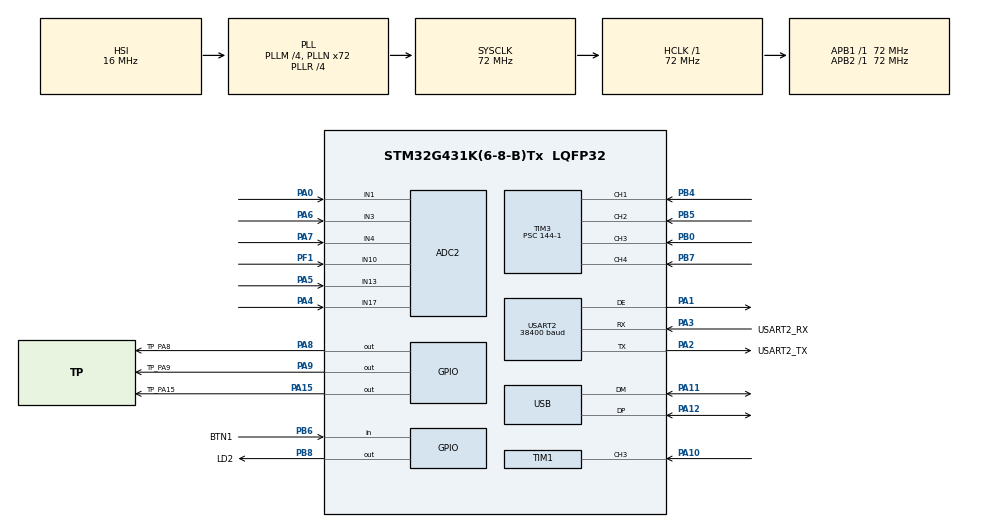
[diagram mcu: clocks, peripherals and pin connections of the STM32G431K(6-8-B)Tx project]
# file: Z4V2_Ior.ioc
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ADC1.Channel-0\#ChannelRegularConversion=ADC_CHANNEL_TEMPSENSOR_ADC1
ADC1.Channel-1\#ChannelRegularConversion=ADC_CHANNEL_VBAT
ADC1.Channel-2\#ChannelRegularConversion=ADC_CHANNEL_VREFINT
ADC1.DMAContinuousRequests=ENABLE
ADC1.ExternalTrigConv=ADC_EXTERNALTRIG_T7_TRGO
ADC1.NbrOfConversion=3
ADC1.NbrOfConversionFlag=1
ADC1.OffsetNumber-0\#ChannelRegularConversion=ADC_OFFSET_NONE
ADC1.OffsetNumber-1\#ChannelRegularConversion=ADC_OFFSET_NONE
ADC1.OffsetNumber-2\#ChannelRegularConversion=ADC_OFFSET_NONE
ADC1.Rank-0\#ChannelRegularConversion=1
ADC1.Rank-1\#ChannelRegularConversion=2
ADC1.Rank-2\#ChannelRegularConversion=3
ADC1.SamplingTime-0\#ChannelRegularConversion=ADC_SAMPLETIME_640CYCLES_5
ADC1.SamplingTime-1\#ChannelRegularConversion=ADC_SAMPLETIME_640CYCLES_5
ADC1.SamplingTime-2\#ChannelRegularConversion=ADC_SAMPLETIME_640CYCLES_5
ADC1.master=1
ADC2.Channel-0\#ChannelRegularConversion=ADC_CHANNEL_1
ADC2.Channel-1\#ChannelRegularConversion=ADC_CHANNEL_10
ADC2.Channel-2\#ChannelRegularConversion=ADC_CHANNEL_3
ADC2.Channel-3\#ChannelRegularConversion=ADC_CHANNEL_4
ADC2.Channel-4\#ChannelRegularConversion=ADC_CHANNEL_13
ADC2.Channel-5\#ChannelRegularConversion=ADC_CHANNEL_17
ADC2.DMAContinuousRequests=ENABLE
ADC2.ExternalTrigConv=ADC_EXTERNALTRIG_T8_TRGO
ADC2.NbrOfConversion=6
ADC2.NbrOfConversionFlag=1
ADC2.OffsetNumber-0\#ChannelRegularConversion=ADC_OFFSET_NONE
ADC2.OffsetNumber-1\#ChannelRegularConversion=ADC_OFFSET_NONE
ADC2.OffsetNumber-2\#ChannelRegularConversion=ADC_OFFSET_NONE
ADC2.OffsetNumber-3\#ChannelRegularConversion=ADC_OFFSET_NONE
ADC2.OffsetNumber-4\#ChannelRegularConversion=ADC_OFFSET_NONE
ADC2.OffsetNumber-5\#ChannelRegularConversion=ADC_OFFSET_NONE
ADC2.Overrun=ADC_OVR_DATA_OVERWRITTEN
ADC2.Rank-0\#ChannelRegularConversion=1
ADC2.Rank-1\#ChannelRegularConversion=2
ADC2.Rank-2\#ChannelRegularConversion=3
ADC2.Rank-3\#ChannelRegularConversion=4
ADC2.Rank-4\#ChannelRegularConversion=5
ADC2.Rank-5\#ChannelRegularConversion=6
ADC2.SamplingTime-0\#ChannelRegularConversion=ADC_SAMPLETIME_640CYCLES_5
ADC2.SamplingTime-1\#ChannelRegularConversion=ADC_SAMPLETIME_47CYCLES_5
ADC2.SamplingTime-2\#ChannelRegularConversion=ADC_SAMPLETIME_640CYCLES_5
ADC2.SamplingTime-3\#ChannelRegularConversion=ADC_SAMPLETIME_640CYCLES_5
ADC2.SamplingTime-4\#ChannelRegularConversion=ADC_SAMPLETIME_640CYCLES_5
ADC2.SamplingTime-5\#ChannelRegularConversion=ADC_SAMPLETIME_640CYCLES_5
Dma.ADC1.1.Direction=DMA_PERIPH_TO_MEMORY
Dma.ADC1.1.EventEnable=DISABLE
Dma.ADC1.1.Instance=DMA1_Channel2
Dma.ADC1.1.MemDataAlignment=DMA_MDATAALIGN_HALFWORD
Dma.ADC1.1.MemInc=DMA_MINC_ENABLE
Dma.ADC1.1.Mode=DMA_CIRCULAR
Dma.ADC1.1.PeriphDataAlignment=DMA_PDATAALIGN_HALFWORD
Dma.ADC1.1.PeriphInc=DMA_PINC_DISABLE
Dma.ADC1.1.Polarity=HAL_DMAMUX_REQ_GEN_RISING
Dma.ADC1.1.Priority=DMA_PRIORITY_LOW
Dma.ADC1.1.RequestNumber=1
Dma.ADC1.1.SignalID=NONE
Dma.ADC1.1.SyncEnable=DISABLE
Dma.ADC1.1.SyncPolarity=HAL_DMAMUX_SYNC_NO_EVENT
Dma.ADC1.1.SyncRequestNumber=1
Dma.ADC1.1.SyncSignalID=NONE
Dma.ADC2.0.Direction=DMA_PERIPH_TO_MEMORY
Dma.ADC2.0.EventEnable=DISABLE
Dma.ADC2.0.Instance=DMA1_Channel1
Dma.ADC2.0.MemDataAlignment=DMA_MDATAALIGN_HALFWORD
Dma.ADC2.0.MemInc=DMA_MINC_ENABLE
Dma.ADC2.0.Mode=DMA_CIRCULAR
Dma.ADC2.0.PeriphDataAlignment=DMA_PDATAALIGN_HALFWORD
Dma.ADC2.0.PeriphInc=DMA_PINC_DISABLE
Dma.ADC2.0.Polarity=HAL_DMAMUX_REQ_GEN_RISING
Dma.ADC2.0.Priority=DMA_PRIORITY_LOW
Dma.ADC2.0.RequestNumber=1
Dma.ADC2.0.SignalID=NONE
Dma.ADC2.0.SyncEnable=DISABLE
Dma.ADC2.0.SyncPolarity=HAL_DMAMUX_SYNC_NO_EVENT
Dma.ADC2.0.SyncRequestNumber=1
Dma.ADC2.0.SyncSignalID=NONE
Dma.Request0=ADC2
Dma.Request1=ADC1
FREERTOS.BinarySemaphores01=sem01,Static,sem01ControlBlock,Available
FREERTOS.Queues01=queue_ADC,8,uint8_t,0,Static,queue_ADCBuffer,queue_ADCControlBlock;queue_USB,128,uint16_t,0,Static,queue_USBBuffer,queue_USBControlBlock
FREERTOS.Tasks01=tsk_USB,24,128,StartDefaultTask,Default,NULL,Static,tsk_USBBuffer,tsk_USBControlBlock;tsk_UI,8,128,StartTask02,Default,NULL,Static,tsk_UIBuffer,tsk_UIControlBlock;tsk_MODBUS,40,128,StartTask03,Default,NULL,Static,tsk_MODBUSBuffer,tsk_MODBUSControlBlock;tsk_Calc,16,256,StartTask04,Default,NULL,Static,tsk_CalcBuffer,tsk_CalcControlBlock
FREERTOS.configENABLE_FPU=1
FREERTOS.configUSE_NEWLIB_REENTRANT=0
Mcu.Family=STM32G4
Mcu.Name=STM32G431K(6-8-B)Tx
Mcu.Package=LQFP32
NVIC.ADC1_2_IRQn=true\:5\:0\:false\:false\:true\:true\:true\:true\:true
NVIC.DMA1_Channel1_IRQn=true\:5\:0\:false\:false\:true\:true\:false\:true\:true
NVIC.DMA1_Channel2_IRQn=true\:5\:0\:false\:false\:true\:true\:false\:true\:true
NVIC.PriorityGroup=NVIC_PRIORITYGROUP_4
NVIC.TIM1_CC_IRQn=true\:5\:0\:false\:false\:true\:true\:true\:true\:true
NVIC.TIM1_TRG_COM_TIM17_IRQn=true\:5\:0\:false\:false\:true\:false\:false\:true\:true
NVIC.TIM3_IRQn=true\:5\:0\:false\:false\:true\:true\:true\:true\:true
NVIC.TimeBase=TIM1_TRG_COM_TIM17_IRQn
NVIC.TimeBaseIP=TIM17
NVIC.USB_HP_IRQn=true\:5\:0\:false\:false\:true\:true\:true\:true\:true
NVIC.USB_LP_IRQn=true\:5\:0\:false\:false\:true\:true\:true\:true\:true
PA0.Mode=IN1-Single-Ended
PA0.Signal=ADC2_IN1
PA1.Mode=Hardware Flow Control (RS485)
PA1.Signal=USART2_DE
PA10.Signal=S_TIM1_CH3
PA11.Mode=Device
PA11.Signal=USB_DM
PA12.Mode=Device
PA12.Signal=USB_DP
PA13.GPIO_Label=T_SWDIO
PA13.Signal=SYS_JTMS-SWDIO
PA14.GPIO_Label=T_SWCLK
PA14.Signal=SYS_JTCK-SWCLK
PA15.GPIO_Label=TP_PA15
PA15.Signal=GPIO_Output
PA2.GPIO_Label=USART2_TX
PA2.Mode=Asynchronous
PA2.Signal=USART2_TX
PA3.GPIO_Label=USART2_RX
PA3.Mode=Asynchronous
PA3.Signal=USART2_RX
PA4.Mode=IN17-Single-Ended
PA4.Signal=ADC2_IN17
PA5.Mode=IN13-Single-Ended
PA5.Signal=ADC2_IN13
PA6.Mode=IN3-Single-Ended
PA6.Signal=ADC2_IN3
PA7.Mode=IN4-Single-Ended
PA7.Signal=ADC2_IN4
PA8.GPIO_Label=TP_PA8
PA8.Signal=GPIO_Output
PA9.GPIO_Label=TP_PA9
PA9.Signal=GPIO_Output
PB0.Signal=S_TIM3_CH3
PB3.GPIO_Label=T_SWO
PB3.Signal=SYS_JTDO-SWO
PB4.Signal=S_TIM3_CH1
PB5.Signal=S_TIM3_CH2
PB6.GPIO_Label=BTN1
PB6.Signal=GPIO_Input
PB7.Signal=S_TIM3_CH4
PB8-BOOT0.GPIO_Label=LD2
PB8-BOOT0.Signal=GPIO_Output
PF0-OSC_IN.Mode=HSE-External-Clock-Source
PF0-OSC_IN.Signal=RCC_OSC_IN
PF1-OSC_OUT.Mode=IN10-Single-Ended
PF1-OSC_OUT.Signal=ADC2_IN10
ProjectManager.HeapSize=0x200
ProjectManager.StackSize=0x400
ProjectManager.TargetToolchain=STM32CubeIDE
RCC.ADC12Freq_Value=72000000
RCC.AHBFreq_Value=72000000
RCC.APB1Freq_Value=72000000
RCC.APB1TimFreq_Value=72000000
RCC.APB2Freq_Value=72000000
RCC.APB2TimFreq_Value=72000000
RCC.CK48CLockSelection=RCC_USBCLKSOURCE_HSI48
RCC.CortexFreq_Value=72000000
RCC.EXTERNAL_CLOCK_VALUE=12288000
RCC.HCLKFreq_Value=72000000
RCC.HSE_VALUE=8000000
RCC.HSI48_VALUE=48000000
RCC.HSI_VALUE=16000000
RCC.LSE_VALUE=32768
RCC.PLLM=RCC_PLLM_DIV4
RCC.PLLN=72
RCC.PLLP=RCC_PLLP_DIV4
RCC.PLLQ=RCC_PLLQ_DIV4
RCC.PLLR=RCC_PLLR_DIV4
RCC.SYSCLKFreq_VALUE=72000000
RCC.SYSCLKSource=RCC_SYSCLKSOURCE_PLLCLK
RCC.USBFreq_Value=48000000
RCC.VCOOutputFreq_Value=288000000
SH.S_TIM1_CH3.0=TIM1_CH3,Input_Capture3_from_TI3
SH.S_TIM3_CH1.0=TIM3_CH1,Input_Capture1_from_TI1
SH.S_TIM3_CH2.0=TIM3_CH2,Input_Capture2_from_TI2
SH.S_TIM3_CH3.0=TIM3_CH3,Input_Capture3_from_TI3
SH.S_TIM3_CH4.0=TIM3_CH4,Input_Capture4_from_TI4
TIM1.Channel-Input_Capture3_from_TI3=TIM_CHANNEL_3
TIM2.Prescaler=144-1
TIM3.Channel-Input_Capture1_from_TI1=TIM_CHANNEL_1
TIM3.Channel-Input_Capture2_from_TI2=TIM_CHANNEL_2
TIM3.Channel-Input_Capture3_from_TI3=TIM_CHANNEL_3
TIM3.Channel-Input_Capture4_from_TI4=TIM_CHANNEL_4
TIM3.Prescaler=144-1
TIM7.PeriodNoDither=10000-1
TIM7.Prescaler=14400-1
TIM7.TIM_MasterOutputTrigger=TIM_TRGO_UPDATE
TIM8.PeriodNoDither=40000-1
TIM8.TIM_MasterOutputTrigger=TIM_TRGO_UPDATE
USART2.BaudRate=38400
USART2.VirtualMode-Asynchronous=VM_ASYNC
USART2.VirtualMode-Hardware\ Flow\ Control\ (RS485)=VM_ASYNC
USB_DEVICE.CLASS_NAME_FS=CDC
USB_DEVICE.VirtualMode=Cdc
USB_DEVICE.VirtualModeFS=Cdc_FS
VP_ADC1_TempSens_Input.Mode=IN-TempSens
VP_ADC1_Vbat_Input.Mode=IN-Vbat
VP_ADC1_Vref_Input.Mode=IN-Vrefint
VP_FREERTOS_VS_CMSIS_V2.Mode=CMSIS_V2
VP_SYS_VS_DBSignals.Mode=DisableDeadBatterySignals
VP_SYS_VS_tim17.Mode=TIM17
VP_TIM1_VS_ClockSourceINT.Mode=Internal
VP_TIM2_VS_ClockSourceINT.Mode=Internal
VP_TIM3_VS_ClockSourceINT.Mode=Internal
VP_TIM7_VS_ClockSourceINT.Mode=Enable_Timer
VP_TIM8_VS_ClockSourceINT.Mode=Internal
VP_USB_DEVICE_VS_USB_DEVICE_CDC_FS.Mode=CDC_FS
board=NUCLEO-G431KB

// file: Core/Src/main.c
/* USER CODE BEGIN Header */
/**
  ******************************************************************************
  * @file           : main.c
  * @brief          : Main program body
  ******************************************************************************
  * @attention
  *
  * Copyright (c) 2026 STMicroelectronics.
  * All rights reserved.
  *
  * This software is licensed under terms that can be found in the LICENSE file
  * in the root directory of this software component.
  * If no LICENSE file comes with this software, it is provided AS-IS.
  *
  ******************************************************************************
  */
/* USER CODE END Header */
#include "main.h"
#include "cmsis_os.h"
#include "usb_device.h"

/* USER CODE BEGIN Includes */
#include "prj.h"
/* USER CODE END Includes */

typedef StaticTask_t osStaticThreadDef_t;
typedef StaticQueue_t osStaticMessageQDef_t;
typedef StaticSemaphore_t osStaticSemaphoreDef_t;

ADC_HandleTypeDef hadc1;
ADC_HandleTypeDef hadc2;
DMA_HandleTypeDef hdma_adc1;
DMA_HandleTypeDef hdma_adc2;

TIM_HandleTypeDef htim1;
TIM_HandleTypeDef htim2;
TIM_HandleTypeDef htim3;
TIM_HandleTypeDef htim7;
TIM_HandleTypeDef htim8;

UART_HandleTypeDef huart2;

/* Definitions for tsk_USB */
osThreadId_t tsk_USBHandle;
uint32_t tsk_USBBuffer[ 128 ];
osStaticThreadDef_t tsk_USBControlBlock;
const osThreadAttr_t tsk_USB_attributes = {
  .name = "tsk_USB",
  .stack_mem = &tsk_USBBuffer[0],
  .stack_size = sizeof(tsk_USBBuffer),
  .cb_mem = &tsk_USBControlBlock,
  .cb_size = sizeof(tsk_USBControlBlock),
  .priority = (osPriority_t) osPriorityNormal,
};
/* Definitions for tsk_UI */
osThreadId_t tsk_UIHandle;
uint32_t tsk_UIBuffer[ 128 ];
osStaticThreadDef_t tsk_UIControlBlock;
const osThreadAttr_t tsk_UI_attributes = {
  .name = "tsk_UI",
  .stack_mem = &tsk_UIBuffer[0],
  .stack_size = sizeof(tsk_UIBuffer),
  .cb_mem = &tsk_UIControlBlock,
  .cb_size = sizeof(tsk_UIControlBlock),
  .priority = (osPriority_t) osPriorityLow,
};
/* Definitions for tsk_MODBUS */
osThreadId_t tsk_MODBUSHandle;
uint32_t tsk_MODBUSBuffer[ 128 ];
osStaticThreadDef_t tsk_MODBUSControlBlock;
const osThreadAttr_t tsk_MODBUS_attributes = {
  .name = "tsk_MODBUS",
  .stack_mem = &tsk_MODBUSBuffer[0],
  .stack_size = sizeof(tsk_MODBUSBuffer),
  .cb_mem = &tsk_MODBUSControlBlock,
  .cb_size = sizeof(tsk_MODBUSControlBlock),
  .priority = (osPriority_t) osPriorityHigh,
};
/* Definitions for tsk_Calc */
osThreadId_t tsk_CalcHandle;
uint32_t tsk_CalcBuffer[ 256 ];
osStaticThreadDef_t tsk_CalcControlBlock;
const osThreadAttr_t tsk_Calc_attributes = {
  .name = "tsk_Calc",
  .stack_mem = &tsk_CalcBuffer[0],
  .stack_size = sizeof(tsk_CalcBuffer),
  .cb_mem = &tsk_CalcControlBlock,
  .cb_size = sizeof(tsk_CalcControlBlock),
  .priority = (osPriority_t) osPriorityBelowNormal,
};
/* Definitions for queue_ADC */
osMessageQueueId_t queue_ADCHandle;
uint8_t queue_ADCBuffer[ 8 * sizeof( uint8_t ) ];
osStaticMessageQDef_t queue_ADCControlBlock;
const osMessageQueueAttr_t queue_ADC_attributes = {
  .name = "queue_ADC",
  .cb_mem = &queue_ADCControlBlock,
  .cb_size = sizeof(queue_ADCControlBlock),
  .mq_mem = &queue_ADCBuffer,
  .mq_size = sizeof(queue_ADCBuffer)
};
/* Definitions for queue_USB */
osMessageQueueId_t queue_USBHandle;
uint8_t queue_USBBuffer[ 128 * sizeof( uint16_t ) ];
osStaticMessageQDef_t queue_USBControlBlock;
const osMessageQueueAttr_t queue_USB_attributes = {
  .name = "queue_USB",
  .cb_mem = &queue_USBControlBlock,
  .cb_size = sizeof(queue_USBControlBlock),
  .mq_mem = &queue_USBBuffer,
  .mq_size = sizeof(queue_USBBuffer)
};
/* Definitions for sem01 */
osSemaphoreId_t sem01Handle;
osStaticSemaphoreDef_t sem01ControlBlock;
const osSemaphoreAttr_t sem01_attributes = {
  .name = "sem01",
  .cb_mem = &sem01ControlBlock,
  .cb_size = sizeof(sem01ControlBlock),
};

void SystemClock_Config(void);
static void MX_GPIO_Init(void);
static void MX_DMA_Init(void);
static void MX_ADC1_Init(void);
static void MX_ADC2_Init(void);
static void MX_USART2_UART_Init(void);
static void MX_TIM1_Init(void);
static void MX_TIM2_Init(void);
static void MX_TIM3_Init(void);
static void MX_TIM7_Init(void);
static void MX_TIM8_Init(void);
void StartDefaultTask(void *argument);
void StartTask02(void *argument);
void StartTask03(void *argument);
void StartTask04(void *argument);

int main(void)
{

  /* MCU Configuration--------------------------------------------------------*/

  /* Reset of all peripherals, Initializes the Flash interface and the Systick. */
  HAL_Init();

  /* Configure the system clock */
  SystemClock_Config();

  /* Initialize all configured peripherals */
  MX_GPIO_Init();
  MX_DMA_Init();
  MX_ADC1_Init();
  MX_ADC2_Init();
  MX_USART2_UART_Init();
  MX_TIM1_Init();
  MX_TIM2_Init();
  MX_TIM3_Init();
  MX_TIM7_Init();
  MX_TIM8_Init();

  /* Init scheduler */
  osKernelInitialize();

  /* Create the semaphores(s) */
  /* creation of sem01 */
  sem01Handle = osSemaphoreNew(1, 1, &sem01_attributes);

  /* Create the queue(s) */
  /* creation of queue_ADC */
  queue_ADCHandle = osMessageQueueNew (8, sizeof(uint8_t), &queue_ADC_attributes);

  /* creation of queue_USB */
  queue_USBHandle = osMessageQueueNew (128, sizeof(uint16_t), &queue_USB_attributes);

  /* Create the thread(s) */
  /* creation of tsk_USB */
  tsk_USBHandle = osThreadNew(StartDefaultTask, NULL, &tsk_USB_attributes);

  /* creation of tsk_UI */
  tsk_UIHandle = osThreadNew(StartTask02, NULL, &tsk_UI_attributes);

  /* creation of tsk_MODBUS */
  tsk_MODBUSHandle = osThreadNew(StartTask03, NULL, &tsk_MODBUS_attributes);

  /* creation of tsk_Calc */
  tsk_CalcHandle = osThreadNew(StartTask04, NULL, &tsk_Calc_attributes);

  /* Start scheduler */
  osKernelStart();

  /* We should never get here as control is now taken by the scheduler */

  /* Infinite loop */
  while (1)
  {

  }
}

void SystemClock_Config(void)
{
  RCC_OscInitTypeDef RCC_OscInitStruct = {0};
  RCC_ClkInitTypeDef RCC_ClkInitStruct = {0};

  /** Configure the main internal regulator output voltage
  */
  HAL_PWREx_ControlVoltageScaling(PWR_REGULATOR_VOLTAGE_SCALE1);

  /** Initializes the RCC Oscillators according to the specified parameters
  * in the RCC_OscInitTypeDef structure.
  */
  RCC_OscInitStruct.OscillatorType = RCC_OSCILLATORTYPE_HSI|RCC_OSCILLATORTYPE_HSI48;
  RCC_OscInitStruct.HSIState = RCC_HSI_ON;
  RCC_OscInitStruct.HSICalibrationValue = RCC_HSICALIBRATION_DEFAULT;
  RCC_OscInitStruct.HSI48State = RCC_HSI48_ON;
  RCC_OscInitStruct.PLL.PLLState = RCC_PLL_ON;
  RCC_OscInitStruct.PLL.PLLSource = RCC_PLLSOURCE_HSI;
  RCC_OscInitStruct.PLL.PLLM = RCC_PLLM_DIV4;
  RCC_OscInitStruct.PLL.PLLN = 72;
  RCC_OscInitStruct.PLL.PLLP = RCC_PLLP_DIV4;
  RCC_OscInitStruct.PLL.PLLQ = RCC_PLLQ_DIV4;
  RCC_OscInitStruct.PLL.PLLR = RCC_PLLR_DIV4;
  if (HAL_RCC_OscConfig(&RCC_OscInitStruct) != HAL_OK)
  {
    Error_Handler();
  }

  /** Initializes the CPU, AHB and APB buses clocks
  */
  RCC_ClkInitStruct.ClockType = RCC_CLOCKTYPE_HCLK|RCC_CLOCKTYPE_SYSCLK
                              |RCC_CLOCKTYPE_PCLK1|RCC_CLOCKTYPE_PCLK2;
  RCC_ClkInitStruct.SYSCLKSource = RCC_SYSCLKSOURCE_PLLCLK;
  RCC_ClkInitStruct.AHBCLKDivider = RCC_SYSCLK_DIV1;
  RCC_ClkInitStruct.APB1CLKDivider = RCC_HCLK_DIV1;
  RCC_ClkInitStruct.APB2CLKDivider = RCC_HCLK_DIV1;

  if (HAL_RCC_ClockConfig(&RCC_ClkInitStruct, FLASH_LATENCY_2) != HAL_OK)
  {
    Error_Handler();
  }
}

static void MX_ADC1_Init(void)
{

  ADC_MultiModeTypeDef multimode = {0};
  ADC_ChannelConfTypeDef sConfig = {0};

  /** Common config
  */
  hadc1.Instance = ADC1;
  hadc1.Init.ClockPrescaler = ADC_CLOCK_SYNC_PCLK_DIV2;
  hadc1.Init.Resolution = ADC_RESOLUTION_12B;
  hadc1.Init.DataAlign = ADC_DATAALIGN_RIGHT;
  hadc1.Init.GainCompensation = 0;
  hadc1.Init.ScanConvMode = ADC_SCAN_ENABLE;
  hadc1.Init.EOCSelection = ADC_EOC_SINGLE_CONV;
  hadc1.Init.LowPowerAutoWait = DISABLE;
  hadc1.Init.ContinuousConvMode = DISABLE;
  hadc1.Init.NbrOfConversion = 3;
  hadc1.Init.DiscontinuousConvMode = DISABLE;
  hadc1.Init.ExternalTrigConv = ADC_EXTERNALTRIG_T7_TRGO;
  hadc1.Init.ExternalTrigConvEdge = ADC_EXTERNALTRIGCONVEDGE_RISING;
  hadc1.Init.DMAContinuousRequests = ENABLE;
  hadc1.Init.Overrun = ADC_OVR_DATA_PRESERVED;
  hadc1.Init.OversamplingMode = DISABLE;
  if (HAL_ADC_Init(&hadc1) != HAL_OK)
  {
    Error_Handler();
  }

  /** Configure the ADC multi-mode
  */
  multimode.Mode = ADC_MODE_INDEPENDENT;
  if (HAL_ADCEx_MultiModeConfigChannel(&hadc1, &multimode) != HAL_OK)
  {
    Error_Handler();
  }

  /** Configure Regular Channel
  */
  sConfig.Channel = ADC_CHANNEL_TEMPSENSOR_ADC1;
  sConfig.Rank = ADC_REGULAR_RANK_1;
  sConfig.SamplingTime = ADC_SAMPLETIME_640CYCLES_5;
  sConfig.SingleDiff = ADC_SINGLE_ENDED;
  sConfig.OffsetNumber = ADC_OFFSET_NONE;
  sConfig.Offset = 0;
  if (HAL_ADC_ConfigChannel(&hadc1, &sConfig) != HAL_OK)
  {
    Error_Handler();
  }

  /** Configure Regular Channel
  */
  sConfig.Channel = ADC_CHANNEL_VBAT;
  sConfig.Rank = ADC_REGULAR_RANK_2;
  if (HAL_ADC_ConfigChannel(&hadc1, &sConfig) != HAL_OK)
  {
    Error_Handler();
  }

  /** Configure Regular Channel
  */
  sConfig.Channel = ADC_CHANNEL_VREFINT;
  sConfig.Rank = ADC_REGULAR_RANK_3;
  if (HAL_ADC_ConfigChannel(&hadc1, &sConfig) != HAL_OK)
  {
    Error_Handler();
  }

}

static void MX_ADC2_Init(void)
{

  ADC_ChannelConfTypeDef sConfig = {0};

  /** Common config
  */
  hadc2.Instance = ADC2;
  hadc2.Init.ClockPrescaler = ADC_CLOCK_SYNC_PCLK_DIV2;
  hadc2.Init.Resolution = ADC_RESOLUTION_12B;
  hadc2.Init.DataAlign = ADC_DATAALIGN_RIGHT;
  hadc2.Init.GainCompensation = 0;
  hadc2.Init.ScanConvMode = ADC_SCAN_ENABLE;
  hadc2.Init.EOCSelection = ADC_EOC_SINGLE_CONV;
  hadc2.Init.LowPowerAutoWait = DISABLE;
  hadc2.Init.ContinuousConvMode = DISABLE;
  hadc2.Init.NbrOfConversion = 6;
  hadc2.Init.DiscontinuousConvMode = DISABLE;
  hadc2.Init.ExternalTrigConv = ADC_EXTERNALTRIG_T8_TRGO;
  hadc2.Init.ExternalTrigConvEdge = ADC_EXTERNALTRIGCONVEDGE_RISING;
  hadc2.Init.DMAContinuousRequests = ENABLE;
  hadc2.Init.Overrun = ADC_OVR_DATA_OVERWRITTEN;
  hadc2.Init.OversamplingMode = DISABLE;
  if (HAL_ADC_Init(&hadc2) != HAL_OK)
  {
    Error_Handler();
  }

  /** Configure Regular Channel
  */
  sConfig.Channel = ADC_CHANNEL_1;
  sConfig.Rank = ADC_REGULAR_RANK_1;
  sConfig.SamplingTime = ADC_SAMPLETIME_640CYCLES_5;
  sConfig.SingleDiff = ADC_SINGLE_ENDED;
  sConfig.OffsetNumber = ADC_OFFSET_NONE;
  sConfig.Offset = 0;
  if (HAL_ADC_ConfigChannel(&hadc2, &sConfig) != HAL_OK)
  {
    Error_Handler();
  }

  /** Configure Regular Channel
  */
  sConfig.Channel = ADC_CHANNEL_10;
  sConfig.Rank = ADC_REGULAR_RANK_2;
  sConfig.SamplingTime = ADC_SAMPLETIME_47CYCLES_5;
  if (HAL_ADC_ConfigChannel(&hadc2, &sConfig) != HAL_OK)
  {
    Error_Handler();
  }

  /** Configure Regular Channel
  */
  sConfig.Channel = ADC_CHANNEL_3;
  sConfig.Rank = ADC_REGULAR_RANK_3;
  sConfig.SamplingTime = ADC_SAMPLETIME_640CYCLES_5;
  if (HAL_ADC_ConfigChannel(&hadc2, &sConfig) != HAL_OK)
  {
    Error_Handler();
  }

  /** Configure Regular Channel
  */
  sConfig.Channel = ADC_CHANNEL_4;
  sConfig.Rank = ADC_REGULAR_RANK_4;
  if (HAL_ADC_ConfigChannel(&hadc2, &sConfig) != HAL_OK)
  {
    Error_Handler();
  }

  /** Configure Regular Channel
  */
  sConfig.Channel = ADC_CHANNEL_13;
  sConfig.Rank = ADC_REGULAR_RANK_5;
  if (HAL_ADC_ConfigChannel(&hadc2, &sConfig) != HAL_OK)
  {
    Error_Handler();
  }

  /** Configure Regular Channel
  */
  sConfig.Channel = ADC_CHANNEL_17;
  sConfig.Rank = ADC_REGULAR_RANK_6;
  if (HAL_ADC_ConfigChannel(&hadc2, &sConfig) != HAL_OK)
  {
    Error_Handler();
  }

}

static void MX_TIM1_Init(void)
{

  TIM_ClockConfigTypeDef sClockSourceConfig = {0};
  TIM_MasterConfigTypeDef sMasterConfig = {0};
  TIM_IC_InitTypeDef sConfigIC = {0};

  htim1.Instance = TIM1;
  htim1.Init.Prescaler = 0;
  htim1.Init.CounterMode = TIM_COUNTERMODE_UP;
  htim1.Init.Period = 65535;
  htim1.Init.ClockDivision = TIM_CLOCKDIVISION_DIV1;
  htim1.Init.RepetitionCounter = 0;
  htim1.Init.AutoReloadPreload = TIM_AUTORELOAD_PRELOAD_DISABLE;
  if (HAL_TIM_Base_Init(&htim1) != HAL_OK)
  {
    Error_Handler();
  }
  sClockSourceConfig.ClockSource = TIM_CLOCKSOURCE_INTERNAL;
  if (HAL_TIM_ConfigClockSource(&htim1, &sClockSourceConfig) != HAL_OK)
  {
    Error_Handler();
  }
  if (HAL_TIM_IC_Init(&htim1) != HAL_OK)
  {
    Error_Handler();
  }
  sMasterConfig.MasterOutputTrigger = TIM_TRGO_RESET;
  sMasterConfig.MasterOutputTrigger2 = TIM_TRGO2_RESET;
  sMasterConfig.MasterSlaveMode = TIM_MASTERSLAVEMODE_DISABLE;
  if (HAL_TIMEx_MasterConfigSynchronization(&htim1, &sMasterConfig) != HAL_OK)
  {
    Error_Handler();
  }
  sConfigIC.ICPolarity = TIM_INPUTCHANNELPOLARITY_RISING;
  sConfigIC.ICSelection = TIM_ICSELECTION_DIRECTTI;
  sConfigIC.ICPrescaler = TIM_ICPSC_DIV1;
  sConfigIC.ICFilter = 0;
  if (HAL_TIM_IC_ConfigChannel(&htim1, &sConfigIC, TIM_CHANNEL_3) != HAL_OK)
  {
    Error_Handler();
  }

}

static void MX_TIM2_Init(void)
{

  TIM_ClockConfigTypeDef sClockSourceConfig = {0};
  TIM_MasterConfigTypeDef sMasterConfig = {0};

  htim2.Instance = TIM2;
  htim2.Init.Prescaler = 144-1;
  htim2.Init.CounterMode = TIM_COUNTERMODE_UP;
  htim2.Init.Period = 4294967295;
  htim2.Init.ClockDivision = TIM_CLOCKDIVISION_DIV1;
  htim2.Init.AutoReloadPreload = TIM_AUTORELOAD_PRELOAD_DISABLE;
  if (HAL_TIM_Base_Init(&htim2) != HAL_OK)
  {
    Error_Handler();
  }
  sClockSourceConfig.ClockSource = TIM_CLOCKSOURCE_INTERNAL;
  if (HAL_TIM_ConfigClockSource(&htim2, &sClockSourceConfig) != HAL_OK)
  {
    Error_Handler();
  }
  sMasterConfig.MasterOutputTrigger = TIM_TRGO_RESET;
  sMasterConfig.MasterSlaveMode = TIM_MASTERSLAVEMODE_DISABLE;
  if (HAL_TIMEx_MasterConfigSynchronization(&htim2, &sMasterConfig) != HAL_OK)
  {
    Error_Handler();
  }

}

static void MX_TIM3_Init(void)
{

  TIM_ClockConfigTypeDef sClockSourceConfig = {0};
  TIM_MasterConfigTypeDef sMasterConfig = {0};
  TIM_IC_InitTypeDef sConfigIC = {0};

  htim3.Instance = TIM3;
  htim3.Init.Prescaler = 144-1;
  htim3.Init.CounterMode = TIM_COUNTERMODE_UP;
  htim3.Init.Period = 65535;
  htim3.Init.ClockDivision = TIM_CLOCKDIVISION_DIV1;
  htim3.Init.AutoReloadPreload = TIM_AUTORELOAD_PRELOAD_DISABLE;
  if (HAL_TIM_Base_Init(&htim3) != HAL_OK)
  {
    Error_Handler();
  }
  sClockSourceConfig.ClockSource = TIM_CLOCKSOURCE_INTERNAL;
  if (HAL_TIM_ConfigClockSource(&htim3, &sClockSourceConfig) != HAL_OK)
  {
    Error_Handler();
  }
  if (HAL_TIM_IC_Init(&htim3) != HAL_OK)
  {
    Error_Handler();
  }
  sMasterConfig.MasterOutputTrigger = TIM_TRGO_RESET;
  sMasterConfig.MasterSlaveMode = TIM_MASTERSLAVEMODE_DISABLE;
  if (HAL_TIMEx_MasterConfigSynchronization(&htim3, &sMasterConfig) != HAL_OK)
  {
    Error_Handler();
  }
  sConfigIC.ICPolarity = TIM_INPUTCHANNELPOLARITY_RISING;
  sConfigIC.ICSelection = TIM_ICSELECTION_DIRECTTI;
  sConfigIC.ICPrescaler = TIM_ICPSC_DIV1;
  sConfigIC.ICFilter = 0;
  if (HAL_TIM_IC_ConfigChannel(&htim3, &sConfigIC, TIM_CHANNEL_1) != HAL_OK)
  {
    Error_Handler();
  }
  if (HAL_TIM_IC_ConfigChannel(&htim3, &sConfigIC, TIM_CHANNEL_2) != HAL_OK)
  {
    Error_Handler();
  }
  if (HAL_TIM_IC_ConfigChannel(&htim3, &sConfigIC, TIM_CHANNEL_3) != HAL_OK)
  {
    Error_Handler();
  }
  if (HAL_TIM_IC_ConfigChannel(&htim3, &sConfigIC, TIM_CHANNEL_4) != HAL_OK)
  {
    Error_Handler();
  }

}

static void MX_TIM7_Init(void)
{

  TIM_MasterConfigTypeDef sMasterConfig = {0};

  htim7.Instance = TIM7;
  htim7.Init.Prescaler = 14400-1;
  htim7.Init.CounterMode = TIM_COUNTERMODE_UP;
  htim7.Init.Period = 9999;
  htim7.Init.AutoReloadPreload = TIM_AUTORELOAD_PRELOAD_DISABLE;
  if (HAL_TIM_Base_Init(&htim7) != HAL_OK)
  {
    Error_Handler();
  }
  sMasterConfig.MasterOutputTrigger = TIM_TRGO_UPDATE;
  sMasterConfig.MasterSlaveMode = TIM_MASTERSLAVEMODE_DISABLE;
  if (HAL_TIMEx_MasterConfigSynchronization(&htim7, &sMasterConfig) != HAL_OK)
  {
    Error_Handler();
  }

}

static void MX_TIM8_Init(void)
{

  TIM_ClockConfigTypeDef sClockSourceConfig = {0};
  TIM_MasterConfigTypeDef sMasterConfig = {0};

  htim8.Instance = TIM8;
  htim8.Init.Prescaler = 0;
  htim8.Init.CounterMode = TIM_COUNTERMODE_UP;
  htim8.Init.Period = 39999;
  htim8.Init.ClockDivision = TIM_CLOCKDIVISION_DIV1;
  htim8.Init.RepetitionCounter = 0;
  htim8.Init.AutoReloadPreload = TIM_AUTORELOAD_PRELOAD_DISABLE;
  if (HAL_TIM_Base_Init(&htim8) != HAL_OK)
  {
    Error_Handler();
  }
  sClockSourceConfig.ClockSource = TIM_CLOCKSOURCE_INTERNAL;
  if (HAL_TIM_ConfigClockSource(&htim8, &sClockSourceConfig) != HAL_OK)
  {
    Error_Handler();
  }
  sMasterConfig.MasterOutputTrigger = TIM_TRGO_UPDATE;
  sMasterConfig.MasterOutputTrigger2 = TIM_TRGO2_RESET;
  sMasterConfig.MasterSlaveMode = TIM_MASTERSLAVEMODE_DISABLE;
  if (HAL_TIMEx_MasterConfigSynchronization(&htim8, &sMasterConfig) != HAL_OK)
  {
    Error_Handler();
  }

}

static void MX_USART2_UART_Init(void)
{

  huart2.Instance = USART2;
  huart2.Init.BaudRate = 38400;
  huart2.Init.WordLength = UART_WORDLENGTH_8B;
  huart2.Init.StopBits = UART_STOPBITS_1;
  huart2.Init.Parity = UART_PARITY_NONE;
  huart2.Init.Mode = UART_MODE_TX_RX;
  huart2.Init.HwFlowCtl = UART_HWCONTROL_NONE;
  huart2.Init.OverSampling = UART_OVERSAMPLING_16;
  huart2.Init.OneBitSampling = UART_ONE_BIT_SAMPLE_DISABLE;
  huart2.Init.ClockPrescaler = UART_PRESCALER_DIV1;
  huart2.AdvancedInit.AdvFeatureInit = UART_ADVFEATURE_NO_INIT;
  if (HAL_RS485Ex_Init(&huart2, UART_DE_POLARITY_HIGH, 0, 0) != HAL_OK)
  {
    Error_Handler();
  }
  if (HAL_UARTEx_SetTxFifoThreshold(&huart2, UART_TXFIFO_THRESHOLD_1_8) != HAL_OK)
  {
    Error_Handler();
  }
  if (HAL_UARTEx_SetRxFifoThreshold(&huart2, UART_RXFIFO_THRESHOLD_1_8) != HAL_OK)
  {
    Error_Handler();
  }
  if (HAL_UARTEx_DisableFifoMode(&huart2) != HAL_OK)
  {
    Error_Handler();
  }

}

static void MX_DMA_Init(void)
{

  /* DMA controller clock enable */
  __HAL_RCC_DMAMUX1_CLK_ENABLE();
  __HAL_RCC_DMA1_CLK_ENABLE();

  /* DMA interrupt init */
  /* DMA1_Channel1_IRQn interrupt configuration */
  HAL_NVIC_SetPriority(DMA1_Channel1_IRQn, 5, 0);
  HAL_NVIC_EnableIRQ(DMA1_Channel1_IRQn);
  /* DMA1_Channel2_IRQn interrupt configuration */
  HAL_NVIC_SetPriority(DMA1_Channel2_IRQn, 5, 0);
  HAL_NVIC_EnableIRQ(DMA1_Channel2_IRQn);

}

static void MX_GPIO_Init(void)
{
  GPIO_InitTypeDef GPIO_InitStruct = {0};

  /* GPIO Ports Clock Enable */
  __HAL_RCC_GPIOF_CLK_ENABLE();
  __HAL_RCC_GPIOA_CLK_ENABLE();
  __HAL_RCC_GPIOB_CLK_ENABLE();

  /*Configure GPIO pin Output Level */
  HAL_GPIO_WritePin(GPIOA, TP_PA8_Pin|TP_PA9_Pin|TP_PA15_Pin, GPIO_PIN_RESET);

  /*Configure GPIO pin Output Level */
  HAL_GPIO_WritePin(LD2_GPIO_Port, LD2_Pin, GPIO_PIN_RESET);

  /*Configure GPIO pins : TP_PA8_Pin TP_PA9_Pin TP_PA15_Pin */
  GPIO_InitStruct.Pin = TP_PA8_Pin|TP_PA9_Pin|TP_PA15_Pin;
  GPIO_InitStruct.Mode = GPIO_MODE_OUTPUT_PP;
  GPIO_InitStruct.Pull = GPIO_NOPULL;
  GPIO_InitStruct.Speed = GPIO_SPEED_FREQ_LOW;
  HAL_GPIO_Init(GPIOA, &GPIO_InitStruct);

  /*Configure GPIO pin : BTN1_Pin */
  GPIO_InitStruct.Pin = BTN1_Pin;
  GPIO_InitStruct.Mode = GPIO_MODE_INPUT;
  GPIO_InitStruct.Pull = GPIO_NOPULL;
  HAL_GPIO_Init(BTN1_GPIO_Port, &GPIO_InitStruct);

  /*Configure GPIO pin : LD2_Pin */
  GPIO_InitStruct.Pin = LD2_Pin;
  GPIO_InitStruct.Mode = GPIO_MODE_OUTPUT_PP;
  GPIO_InitStruct.Pull = GPIO_NOPULL;
  GPIO_InitStruct.Speed = GPIO_SPEED_FREQ_LOW;
  HAL_GPIO_Init(LD2_GPIO_Port, &GPIO_InitStruct);

}

void StartDefaultTask(void *argument)
{
  /* init code for USB_Device */
  MX_USB_Device_Init();
  for(;;)
  {
    osDelay(1);
  }
}

void StartTask02(void *argument)
{
  for(;;)
  {
    osDelay(1);
  }
}

void StartTask03(void *argument)
{
  for(;;)
  {
    osDelay(1);
  }
}

void StartTask04(void *argument)
{
  /* USER CODE BEGIN StartTask04 */
  tsk_calc();
  /* Infinite loop */
  for(;;)
  {
    osDelay(1);
  }
  /* USER CODE END StartTask04 */
}

void HAL_TIM_PeriodElapsedCallback(TIM_HandleTypeDef *htim)
{
  if (htim->Instance == TIM17)
  {
    HAL_IncTick();
  }
}

void Error_Handler(void)
{
  __disable_irq();
  while (1)
  {
  }
}
